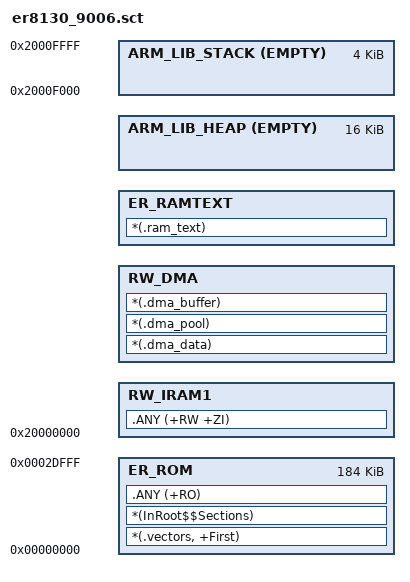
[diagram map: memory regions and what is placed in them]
;*****************************************************************************
; Scatter file for ER8130 (er8131p9) - ARM Compiler 5 / Keil uVision
;
; Translated from ldscripts/default_9006.ld (GNU build). Memory map:
;   FLASH : 0x00000000, length 0x0002E000 (184 KB)
;   RAM   : 0x20000000, length 0x00010000 ( 64 KB)
;
; HARDWARE CONSTRAINT: the DMA engine can only access the first 48 KB of RAM,
; i.e. addresses below 0x2000C000. The .dma_* sections are kept under that
; ceiling (enforced by the ScatterAssert below).
;
; Heap / stack sizes mirror the Eclipse build defines:
;   __HEAP_SIZE  = 0x4000 (16 KB)
;   __STACK_SIZE = 0x1000 ( 4 KB)
;*****************************************************************************

LR_ROM 0x00000000 0x0002E000
{
    ; ---- Code & read-only data in FLASH ----
    ER_ROM 0x00000000 0x0002E000
    {
        *(.vectors, +First)         ; CMSIS C vector table (__Vectors)
        *(InRoot$$Sections)         ; C library / scatter-load code that must stay in root
        .ANY (+RO)                  ; all other code + rodata
    }

    ; ---- Initialised data (.data) and zero-init (.bss) ----
    RW_IRAM1 0x20000000
    {
        .ANY (+RW +ZI)
    }

    ; ---- DMA pool (must remain within the first 48 KB of RAM) ----
    ; Sections produced by DMA_ATTR / DMA_DATA_ATTR / STATIC_DMA* in wise_core.h.
    ; Named selectors take priority over the .ANY above, so these land here.
    ; All three selectors are kept for forward-compatibility; a minimal app may
    ; only populate .dma_pool, which makes armlink emit L6314W "no section
    ; matches" for the empty ones. That warning is suppressed via the linker
    ; option --diag_suppress=6314 (Options -> Linker -> Misc controls).
    RW_DMA +0 ALIGN 4
    {
        *(.dma_data)                ; initialised DMA data (copied from flash)
        *(.dma_pool)                ; zero-init DMA buffers
        *(.dma_buffer)
    }
    ScatterAssert(ImageLimit(RW_DMA) <= 0x2000C000)   ; 48 KB DMA boundary

    ; ---- RAM functions: stored in flash, executed from RAM (.ram_text) ----
    ; __main copies this region from its flash load address to RAM at startup.
    ER_RAMTEXT +0 ALIGN 16
    {
        *(.ram_text)
    }

    ; ---- Heap then stack at the top of RAM ----
    ARM_LIB_HEAP  +0 EMPTY 0x00004000 { }            ; __HEAP_SIZE,  grows up
    ScatterAssert(ImageLimit(ARM_LIB_HEAP) <= 0x2000F000)   ; must not collide with stack

    ARM_LIB_STACK 0x20010000 EMPTY -0x00001000 { }   ; __STACK_SIZE, grows down from top of RAM
}
